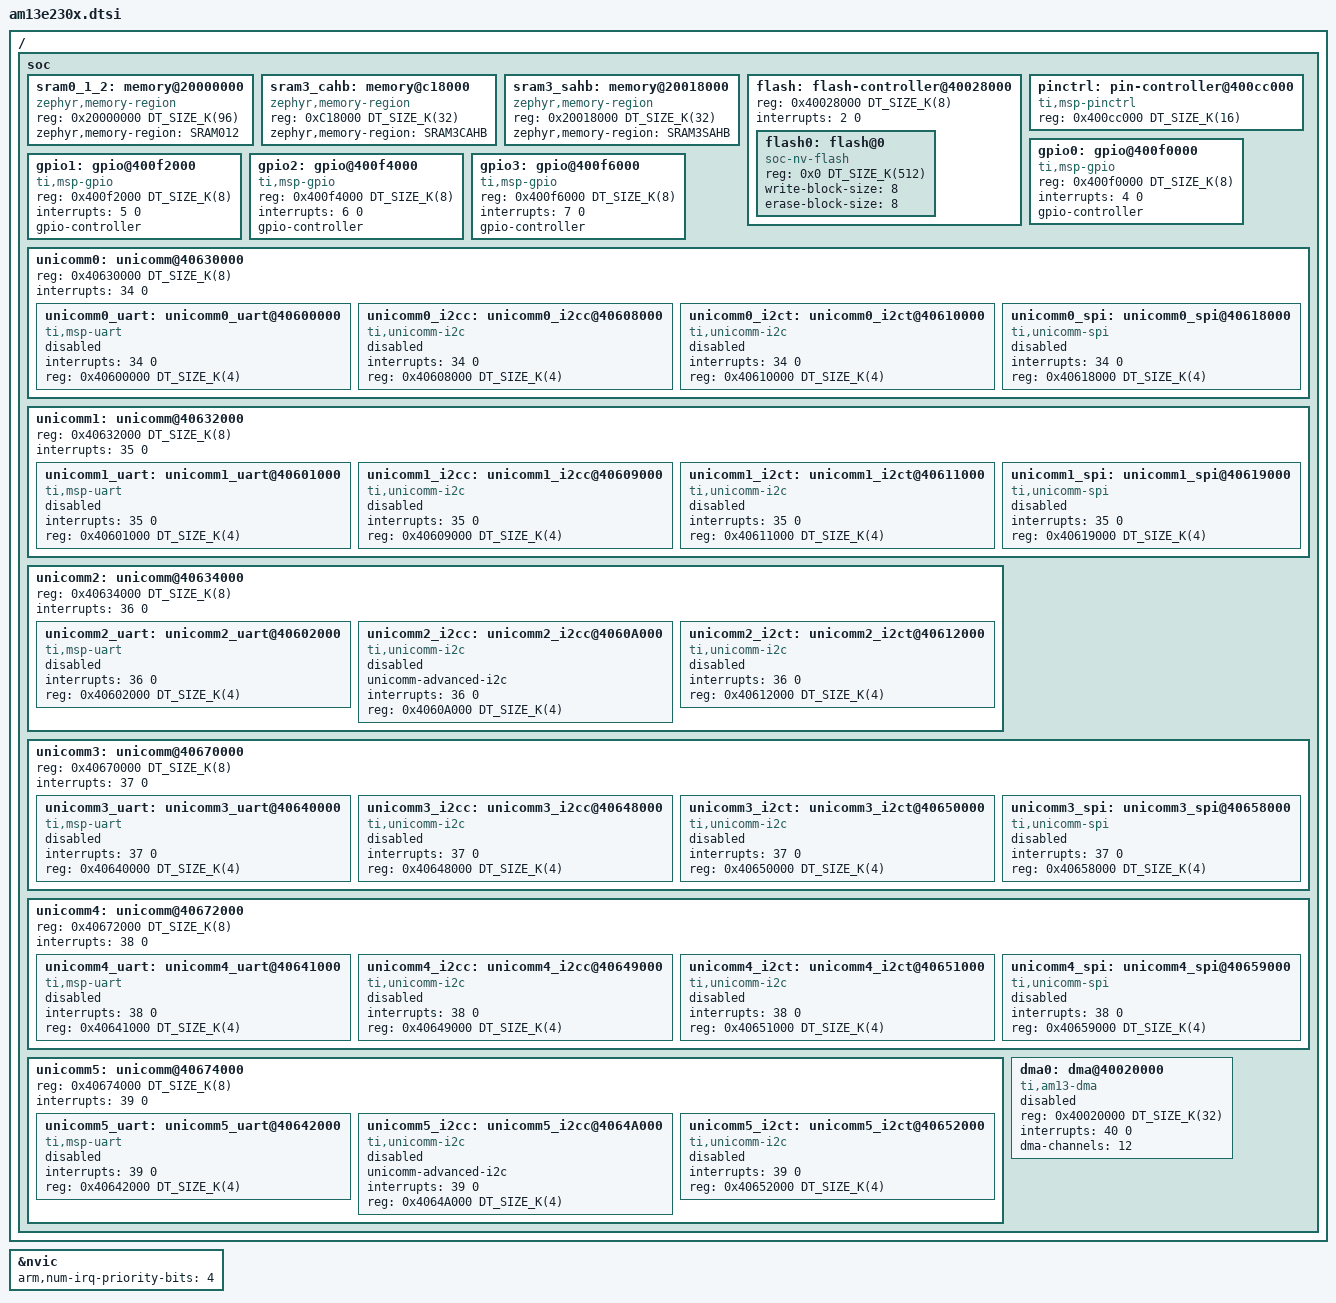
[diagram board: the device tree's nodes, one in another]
/*
 * Copyright (c) 2026 Texas Instruments Incorporated
 *
 * SPDX-License-Identifier: Apache-2.0
 */

#include "am13e.dtsi"

/ {
	#address-cells = <1>;
	#size-cells = <1>;

	soc {
		sram0_1_2: memory@20000000 {
			compatible = "zephyr,memory-region";
			reg = <0x20000000 DT_SIZE_K(96)>;
			zephyr,memory-region = "SRAM012";
		};

		sram3_cahb: memory@c18000 {
			compatible = "zephyr,memory-region";
			reg = <0xC18000 DT_SIZE_K(32)>;
			zephyr,memory-region = "SRAM3CAHB";
		};

		sram3_sahb: memory@20018000 {
			compatible = "zephyr,memory-region";
			reg = <0x20018000 DT_SIZE_K(32)>;
			zephyr,memory-region = "SRAM3SAHB";
		};

		flash: flash-controller@40028000 {
			reg = <0x40028000 DT_SIZE_K(8)>;
			interrupts = <2 0>;

			#address-cells = <1>;
			#size-cells = <1>;

			flash0: flash@0 {
				compatible = "soc-nv-flash";
				reg = <0x0 DT_SIZE_K(512)>;
				write-block-size = <8>;
				erase-block-size = <8>;
			};
		};

		pinctrl: pin-controller@400cc000 {
			compatible = "ti,msp-pinctrl";
			reg = <0x400cc000 DT_SIZE_K(16)>;
		};

		gpio0: gpio@400f0000 {
			compatible = "ti,msp-gpio";
			reg = <0x400f0000 DT_SIZE_K(8)>;
			interrupts = <4 0>;
			#gpio-cells = <2>;
			gpio-controller;
		};

		gpio1: gpio@400f2000 {
			compatible = "ti,msp-gpio";
			reg = <0x400f2000 DT_SIZE_K(8)>;
			interrupts = <5 0>;
			#gpio-cells = <2>;
			gpio-controller;
		};

		gpio2: gpio@400f4000 {
			compatible = "ti,msp-gpio";
			reg = <0x400f4000 DT_SIZE_K(8)>;
			interrupts = <6 0>;
			#gpio-cells = <2>;
			gpio-controller;
		};

		gpio3: gpio@400f6000 {
			compatible = "ti,msp-gpio";
			reg = <0x400f6000 DT_SIZE_K(8)>;
			interrupts = <7 0>;
			#gpio-cells = <2>;
			gpio-controller;
		};

		unicomm0: unicomm@40630000 {
			reg = <0x40630000 DT_SIZE_K(8)>;
			interrupts = <34 0>;
			#address-cells = <1>;
			#size-cells = <1>;

			unicomm0_uart: unicomm0_uart@40600000 {
				compatible = "ti,msp-uart";
				interrupts = <34 0>;
				reg = <0x40600000 DT_SIZE_K(4)>;
				status = "disabled";
			};

			unicomm0_i2cc: unicomm0_i2cc@40608000 {
				compatible = "ti,unicomm-i2c";
				#address-cells = <1>;
				#size-cells = <0>;
				interrupts = <34 0>;
				reg = <0x40608000 DT_SIZE_K(4)>;
				status = "disabled";
			};

			unicomm0_i2ct: unicomm0_i2ct@40610000 {
				compatible = "ti,unicomm-i2c";
				#address-cells = <1>;
				#size-cells = <0>;
				interrupts = <34 0>;
				reg = <0x40610000 DT_SIZE_K(4)>;
				status = "disabled";
			};

			unicomm0_spi: unicomm0_spi@40618000 {
				compatible = "ti,unicomm-spi";
				#address-cells = <1>;
				#size-cells = <0>;
				interrupts = <34 0>;
				reg = <0x40618000 DT_SIZE_K(4)>;
				status = "disabled";
			};
		};

		unicomm1: unicomm@40632000 {
			reg = <0x40632000 DT_SIZE_K(8)>;
			interrupts = <35 0>;
			#address-cells = <1>;
			#size-cells = <1>;

			unicomm1_uart: unicomm1_uart@40601000 {
				compatible = "ti,msp-uart";
				interrupts = <35 0>;
				reg = <0x40601000 DT_SIZE_K(4)>;
				status = "disabled";
			};

			unicomm1_i2cc: unicomm1_i2cc@40609000 {
				compatible = "ti,unicomm-i2c";
				#address-cells = <1>;
				#size-cells = <0>;
				interrupts = <35 0>;
				reg = <0x40609000 DT_SIZE_K(4)>;
				status = "disabled";
			};

			unicomm1_i2ct: unicomm1_i2ct@40611000 {
				compatible = "ti,unicomm-i2c";
				#address-cells = <1>;
				#size-cells = <0>;
				interrupts = <35 0>;
				reg = <0x40611000 DT_SIZE_K(4)>;
				status = "disabled";
			};

			unicomm1_spi: unicomm1_spi@40619000 {
				compatible = "ti,unicomm-spi";
				#address-cells = <1>;
				#size-cells = <0>;
				interrupts = <35 0>;
				reg = <0x40619000 DT_SIZE_K(4)>;
				status = "disabled";
			};
		};

		unicomm2: unicomm@40634000 {
			reg = <0x40634000 DT_SIZE_K(8)>;
			interrupts = <36 0>;
			#address-cells = <1>;
			#size-cells = <1>;

			unicomm2_uart: unicomm2_uart@40602000 {
				compatible = "ti,msp-uart";
				interrupts = <36 0>;
				reg = <0x40602000 DT_SIZE_K(4)>;
				status = "disabled";
			};

			unicomm2_i2cc: unicomm2_i2cc@4060A000 {
				compatible = "ti,unicomm-i2c";
				unicomm-advanced-i2c;
				#address-cells = <1>;
				#size-cells = <0>;
				interrupts = <36 0>;
				reg = <0x4060A000 DT_SIZE_K(4)>;
				status = "disabled";
			};

			unicomm2_i2ct: unicomm2_i2ct@40612000 {
				compatible = "ti,unicomm-i2c";
				#address-cells = <1>;
				#size-cells = <0>;
				interrupts = <36 0>;
				reg = <0x40612000 DT_SIZE_K(4)>;
				status = "disabled";
			};
		};

		unicomm3: unicomm@40670000 {
			reg = <0x40670000 DT_SIZE_K(8)>;
			interrupts = <37 0>;
			#address-cells = <1>;
			#size-cells = <1>;

			unicomm3_uart: unicomm3_uart@40640000 {
				compatible = "ti,msp-uart";
				interrupts = <37 0>;
				reg = <0x40640000 DT_SIZE_K(4)>;
				status = "disabled";
			};

			unicomm3_i2cc: unicomm3_i2cc@40648000 {
				compatible = "ti,unicomm-i2c";
				#address-cells = <1>;
				#size-cells = <0>;
				interrupts = <37 0>;
				reg = <0x40648000 DT_SIZE_K(4)>;
				status = "disabled";
			};

			unicomm3_i2ct: unicomm3_i2ct@40650000 {
				compatible = "ti,unicomm-i2c";
				#address-cells = <1>;
				#size-cells = <0>;
				interrupts = <37 0>;
				reg = <0x40650000 DT_SIZE_K(4)>;
				status = "disabled";
			};

			unicomm3_spi: unicomm3_spi@40658000 {
				compatible = "ti,unicomm-spi";
				#address-cells = <1>;
				#size-cells = <0>;
				interrupts = <37 0>;
				reg = <0x40658000 DT_SIZE_K(4)>;
				status = "disabled";
			};
		};

		unicomm4: unicomm@40672000 {
			reg = <0x40672000 DT_SIZE_K(8)>;
			interrupts = <38 0>;
			#address-cells = <1>;
			#size-cells = <1>;

			unicomm4_uart: unicomm4_uart@40641000 {
				compatible = "ti,msp-uart";
				interrupts = <38 0>;
				reg = <0x40641000 DT_SIZE_K(4)>;
				status = "disabled";
			};

			unicomm4_i2cc: unicomm4_i2cc@40649000 {
				compatible = "ti,unicomm-i2c";
				#address-cells = <1>;
				#size-cells = <0>;
				interrupts = <38 0>;
				reg = <0x40649000 DT_SIZE_K(4)>;
				status = "disabled";
			};

			unicomm4_i2ct: unicomm4_i2ct@40651000 {
				compatible = "ti,unicomm-i2c";
				#address-cells = <1>;
				#size-cells = <0>;
				interrupts = <38 0>;
				reg = <0x40651000 DT_SIZE_K(4)>;
				status = "disabled";
			};

			unicomm4_spi: unicomm4_spi@40659000 {
				compatible = "ti,unicomm-spi";
				#address-cells = <1>;
				#size-cells = <0>;
				interrupts = <38 0>;
				reg = <0x40659000 DT_SIZE_K(4)>;
				status = "disabled";
			};
		};

		unicomm5: unicomm@40674000 {
			reg = <0x40674000 DT_SIZE_K(8)>;
			interrupts = <39 0>;
			#address-cells = <1>;
			#size-cells = <1>;

			unicomm5_uart: unicomm5_uart@40642000 {
				compatible = "ti,msp-uart";
				interrupts = <39 0>;
				reg = <0x40642000 DT_SIZE_K(4)>;
				status = "disabled";
			};

			unicomm5_i2cc: unicomm5_i2cc@4064A000 {
				compatible = "ti,unicomm-i2c";
				unicomm-advanced-i2c;
				#address-cells = <1>;
				#size-cells = <0>;
				interrupts = <39 0>;
				reg = <0x4064A000 DT_SIZE_K(4)>;
				status = "disabled";
			};

			unicomm5_i2ct: unicomm5_i2ct@40652000 {
				compatible = "ti,unicomm-i2c";
				#address-cells = <1>;
				#size-cells = <0>;
				interrupts = <39 0>;
				reg = <0x40652000 DT_SIZE_K(4)>;
				status = "disabled";
			};
		};

		dma0: dma@40020000 {
			compatible = "ti,am13-dma";
			reg = <0x40020000 DT_SIZE_K(32)>;
			interrupts = <40 0>;
			status = "disabled";
			#dma-cells = <1>;

			dma-channels = <12>;
		};
	};
};

&nvic {
	arm,num-irq-priority-bits = <4>;
};
